LIN_description_file;
LIN_protocol_version = "J2602_1_1.0";
LIN_language_version = "J2602_3_1.0";
LIN_speed = 19.2 kbps;

Nodes {
  Master: BMS, 10 ms, 0.5 ms, 48 bits, 40 %;
  Slaves: BPS_VICM_LIN7_connector, BPS2_VICM_LIN7_connector ;
}

Signals {
  BPS_Pressure: 14, 0, BPS_VICM_LIN7_connector, BMS ;
  BPS2_Pressure: 14, 0, BPS2_VICM_LIN7_connector, BMS ;
  BPS_ARC: 2, 0, BPS_VICM_LIN7_connector, BMS ;
  BPS2_ARC: 2, 0, BPS2_VICM_LIN7_connector, BMS ;
  BPS_CommErr: 3, 0, BPS_VICM_LIN7_connector, BMS ;
  BPS2_CommErr: 3, 0, BPS2_VICM_LIN7_connector, BMS ;
  back0: 16, 0, BPS_VICM_LIN7_connector, BMS ;
  back1: 16, 0, BPS_VICM_LIN7_connector, BMS ;
  back2: 8, 0, BPS_VICM_LIN7_connector, BMS ;
  back4: 3, 0, BPS_VICM_LIN7_connector, BMS ;
  back3: 2, 0, BPS_VICM_LIN7_connector, BMS ;
  back5: 2, 0, BPS2_VICM_LIN7_connector, BMS ;
  back6: 16, 0, BPS2_VICM_LIN7_connector, BMS ;
  back7: 16, 0, BPS2_VICM_LIN7_connector, BMS ;
  back8: 8, 0, BPS2_VICM_LIN7_connector, BMS ;
  back9: 3, 0, BPS2_VICM_LIN7_connector, BMS ;
}

Frames {
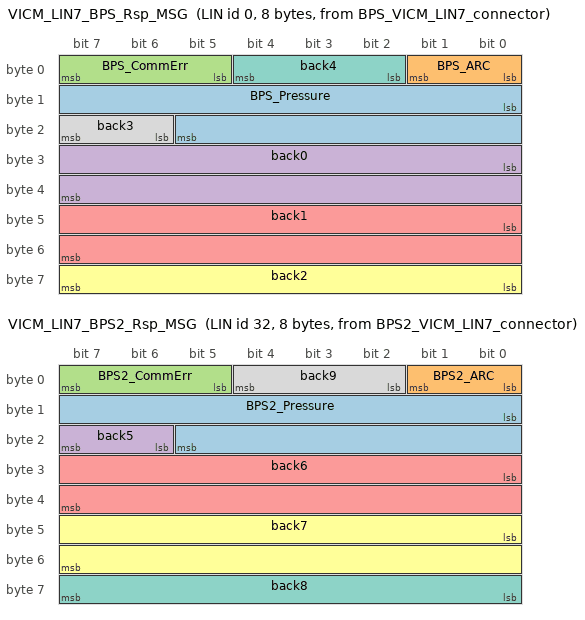
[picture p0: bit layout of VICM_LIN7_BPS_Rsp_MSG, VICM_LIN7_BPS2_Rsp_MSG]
  VICM_LIN7_BPS_Rsp_MSG: 0, BPS_VICM_LIN7_connector, 8 {
    BPS_Pressure, 8 ;
    BPS_ARC, 0 ;
    BPS_CommErr, 5 ;
    back0, 24 ;
    back1, 40 ;
    back2, 56 ;
    back4, 2 ;
    back3, 22 ;
  }
  VICM_LIN7_BPS2_Rsp_MSG: 32, BPS2_VICM_LIN7_connector, 8 {
    BPS2_Pressure, 8 ;
    BPS2_ARC, 0 ;
    BPS2_CommErr, 5 ;
    back5, 22 ;
    back6, 24 ;
    back7, 40 ;
    back8, 56 ;
    back9, 2 ;
  }
}

Node_attributes {
  BPS_VICM_LIN7_connector{
    LIN_protocol = "J2602_1_1.0" ;
    configured_NAD = 0x60 ;
    product_id = 0x100E, 0x1, 1 ;
    response_error = BPS_CommErr ;
    P2_min = 0 ms ;
    ST_min = 0 ms ;
    configurable_frames {
      VICM_LIN7_BPS_Rsp_MSG = 0x0 ;
    }
    response_tolerance = 40 % ;
    wakeup_time = 100 ms;
    poweron_time = 200 ms;
  }
  BPS2_VICM_LIN7_connector{
    LIN_protocol = "J2602_1_1.0" ;
    configured_NAD = 0x68 ;
    product_id = 0x100E, 0x2, 1 ;
    response_error = BPS2_CommErr ;
    P2_min = 0 ms ;
    ST_min = 0 ms ;
    configurable_frames {
      VICM_LIN7_BPS2_Rsp_MSG = 0x20 ;
    }
    response_tolerance = 40 % ;
    wakeup_time = 100 ms;
    poweron_time = 200 ms;
  }
}

Schedule_tables {
 Cycle {
    VICM_LIN7_BPS2_Rsp_MSG delay 50 ms ;
    VICM_LIN7_BPS_Rsp_MSG delay 50 ms ;
  }
}

Signal_encoding_types {
  BPS1_Pressure_Encoding {
    physical_value, 0, 16383, 0.018174327, -12.75, "kPa" ;
    logical_value, 1, "Over Voltage" ;
    logical_value, 2, "ASIC Fail" ;
  }
  BPS2_Pressure_Encoding {
    physical_value, 0, 16383, 0.018174327, -12.75, "kPa" ;
    logical_value, 1, "Over Voltage" ;
    logical_value, 2, "Asic fail" ;
  }
  BPS_CommErr_Encoding {
    logical_value, 0, "New Value Description" ;
    logical_value, 1, "New Value Description" ;
    logical_value, 2, "New Value Description" ;
    logical_value, 3, "New Value Description" ;
    logical_value, 4, "New Value Description" ;
    logical_value, 5, "New Value Description" ;
    logical_value, 6, "New Value Description" ;
    logical_value, 7, "New Value Description" ;
  }
  Vol_Encoding {
    physical_value, 0, 0, 0.001, 0, "V" ;
  }
}

Signal_representation {
  BPS1_Pressure_Encoding: BPS_Pressure ;
  BPS2_Pressure_Encoding: BPS2_Pressure ;
  BPS_CommErr_Encoding: BPS_CommErr, BPS2_CommErr ;
}
